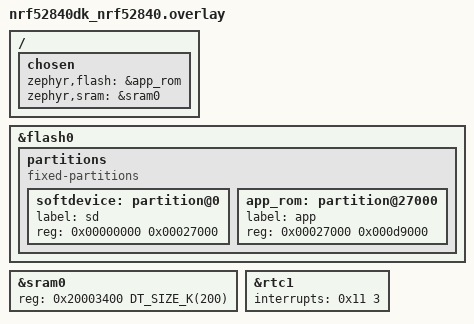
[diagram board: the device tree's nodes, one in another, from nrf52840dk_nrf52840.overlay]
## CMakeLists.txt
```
#
# Copyright (c) 2025 Nordic Semiconductor ASA
#
# SPDX-License-Identifier: LicenseRef-Nordic-5-Clause
#

cmake_minimum_required(VERSION 3.20.0)

find_package(Zephyr REQUIRED HINTS $ENV{ZEPHYR_BASE})
project(ble_services)

target_sources(app PRIVATE src/main.c)
```

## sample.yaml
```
sample:
  name: BLE LBS Service
tests:
  sample.ble_lbs_service:
    sysbuild: true
    build_only: true
    integration_platforms:
      - nrf52840dk/nrf52840
    platform_allow:
      - nrf52840dk/nrf52840
    tags: ci_build
```

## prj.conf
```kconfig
CONFIG_MULTITHREADING=n
CONFIG_ZERO_LATENCY_IRQS=y
CONFIG_CLOCK_CONTROL=n

CONFIG_NRF_SDH=y
CONFIG_SOFTDEVICE_S140=y

CONFIG_LOG=y
CONFIG_LOG_MODE_MINIMAL=y

CONFIG_BLE_ADV=y
CONFIG_BLE_ADV_EXTENDED_ADVERTISING=n
CONFIG_BLE_ADV_DIRECTED_ADVERTISING=n

# BLE connection parameter
CONFIG_BLE_CONN_PARAMS=y
# For testing
CONFIG_NRF_SDH_BLE_GATT_MAX_MTU_SIZE=100
CONFIG_BLE_CONN_PARAMS_DATA_LENGTH=100

CONFIG_EVENT_SCHEDULER=y

CONFIG_BLE_LBS=y
# Device information service
CONFIG_BLE_DIS=y
CONFIG_BLE_DIS_SERIAL_NUMBER="ABCD"
CONFIG_BLE_DIS_HW_REVISION="hw 54.15.0"
CONFIG_BLE_DIS_FW_REVISION="fw 17.2.0" # wink
CONFIG_BLE_DIS_SW_REVISION="sw 1.0.0"

# Shrink
CONFIG_GPIO=n
CONFIG_PARTITION_MANAGER_ENABLED=n
CONFIG_LOG_BACKEND_RTT=n

# Required for LBS vendor UUID
CONFIG_NRF_SDH_BLE_VS_UUID_COUNT=1

CONFIG_LITE_TIMER=y
CONFIG_NRFX_GPIOTE0=y

CONFIG_LITE_BUTTONS=y
```

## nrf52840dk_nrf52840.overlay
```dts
&flash0 {
	partitions {
		compatible = "fixed-partitions";
		#address-cells = <1>;
		#size-cells = <1>;
		softdevice: partition@0 {
			label = "sd";
			reg = <0x00000000 0x00027000>;
		};
		app_rom: partition@27000 {
			label = "app";
			reg = <0x00027000 0x000d9000>;
		};
	};
};

&sram0 {
	reg = <0x20003400 DT_SIZE_K(200)>;
};


/ {
	chosen {
		zephyr,flash = &app_rom;
		zephyr,sram = &sram0;
	};
};

/* Lower the priority of the application RTC. Required when timeout handlers call softdevice svcs */
&rtc1 {
	interrupts = <0x11 3>;
};
```

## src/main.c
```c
/*
 * Copyright (c) 2025 Nordic Semiconductor ASA
 *
 * SPDX-License-Identifier: LicenseRef-Nordic-5-Clause
 */

#include <nrf_sdh.h>
#include <nrf_sdh_ble.h>
#include <nrf_sdh_soc.h>
#include <event_scheduler.h>
#include <ble_adv.h>
#include <ble_gap.h>
#include <bluetooth/services/ble_lbs.h>
#include <bluetooth/services/ble_dis.h>
#include <zephyr/kernel.h> /* k_busy_wait() */
#include <zephyr/sys_clock.h> /* USEC_PER_SEC */
#include <zephyr/sys/printk.h>

#include <lite_buttons.h>

#define INPUT_PIN 11
#define CONN_TAG 1

BLE_ADV_DEF(ble_adv); /* BLE advertising instance */
BLE_LBS_DEF(ble_lbs); /* BLE LED Button Service instance */

/* Device information service is single-instance */

static uint16_t conn_handle;

static void on_ble_evt(const ble_evt_t *evt, void *ctx)
{
	int err;

	switch (evt->header.evt_id) {
	case BLE_GAP_EVT_CONNECTED:
		printk("Peer connected\n");
		conn_handle = evt->evt.gap_evt.conn_handle;
		err = sd_ble_gatts_sys_attr_set(conn_handle, NULL, 0, 0);
		if (err) {
			printk("Failed to set system attributes, nrf_error %d", err);
		}
		break;

	case BLE_GAP_EVT_AUTH_STATUS:
		printk("Authentication status: %#x\n",
		       evt->evt.gap_evt.params.auth_status.auth_status);
		break;

	case BLE_GAP_EVT_SEC_PARAMS_REQUEST:
		/* Pairing not supported */
		err = sd_ble_gap_sec_params_reply(evt->evt.gap_evt.conn_handle,
						  BLE_GAP_SEC_STATUS_PAIRING_NOT_SUPP, NULL, NULL);
		if (err) {
			printk("Failed to reply with Security params, nrf_error %d\n", err);
		}
		break;

	case BLE_GATTS_EVT_SYS_ATTR_MISSING:
		printk("BLE_GATTS_EVT_SYS_ATTR_MISSING\n");
		/* No system attributes have been stored */
		err = sd_ble_gatts_sys_attr_set(conn_handle, NULL, 0, 0);
		if (err) {
			printk("Failed to set system attributes, nrf_error %d", err);
		}
		break;
	}
}
NRF_SDH_BLE_OBSERVER(sdh_ble, on_ble_evt, NULL, 0);

static void ble_adv_evt_handler(enum ble_adv_evt evt)
{
	/* ignore */
}

static void ble_adv_error_handler(uint32_t error)
{
	printk("Advertising error %d\n", error);
}

static void ble_lbs_evt_handler(uint16_t conn_handle, struct ble_lbs *lbs, uint8_t new_state)
{
}

static void button_handler(uint8_t pin, uint8_t action)
{
	printk("Button event callback: %d, %d\n", pin, action);
	ble_lbs_on_button_change(&ble_lbs, conn_handle, action);
}

int main(void)
{
	int err;
	uint32_t ram_start;
	struct ble_adv_config ble_adv_config = {
		.conn_cfg_tag = CONN_TAG,
		.evt_handler = ble_adv_evt_handler,
		.error_handler = ble_adv_error_handler,
		.adv_data = {
			.name_type = BLE_ADV_DATA_FULL_NAME,
			.flags = BLE_GAP_ADV_FLAGS_LE_ONLY_GENERAL_DISC_MODE,
		},
	};
	struct ble_lbs_config lbs_cfg = {
		.led_write_handler = ble_lbs_evt_handler,
	};

	err = nrf_sdh_enable_request();
	if (err) {
		printk("Failed to enable SoftDevice, err %d\n", err);
		return -1;
	}

	printk("SoftDevice enabled\n");

	nrf_sdh_ble_app_ram_start_get(&ram_start);

	err = nrf_sdh_ble_default_cfg_set(CONN_TAG);
	if (err) {
		printk("Failed to setup default configuration, err %d\n", err);
		return -1;
	}

	err = nrf_sdh_ble_enable(ram_start);
	if (err) {
		printk("Failed to enable BLE, err %d\n", err);
		return -1;
	}

	printk("Bluetooth is enabled!\n");

	err = lite_buttons_init(
		&(struct lite_buttons_config){
			.pin_number = INPUT_PIN,
			.active_state = LITE_BUTTONS_ACTIVE_LOW,
			.pull_config = LITE_BUTTONS_PIN_PULLUP,
			.handler = button_handler,
		},
		1, 10);
	if (err) {
		printk("lite_buttons_init error: %d\n", err);
		return err;
	}

	err = lite_buttons_enable();
	if (err) {
		printk("lite_buttons_enable error: %d\n", err);
		return err;
	}

	err = ble_lbs_init(&ble_lbs, &lbs_cfg);
	if (err) {
		printk("Failed to setup battery service, err %d\n", err);
		return -1;
	}

	printk("LBS initialized\n");

	err = ble_dis_init();
	if (err) {
		printk("Failed to initialize device information service, err %d\n", err);
		return -1;
	}

	err = ble_adv_init(&ble_adv, &ble_adv_config);
	if (err) {
		printk("Failed to initialize BLE advertising, err %d\n", err);
		return -1;
	}

	err = ble_adv_start(&ble_adv, BLE_ADV_MODE_FAST);
	if (err) {
		printk("Failed to start advertising, err %d\n", err);
		return -1;
	}

	while (true) {
		sd_app_evt_wait();
		k_busy_wait(1 * USEC_PER_SEC);
		event_scheduler_process();
	}

	err = nrf_sdh_disable_request();
	if (err) {
		printk("Failed to disable SoftDevice, err %d\n", err);
		return -1;
	}

	printk("SoftDevice disabled\n");

	return 0;
}
```
